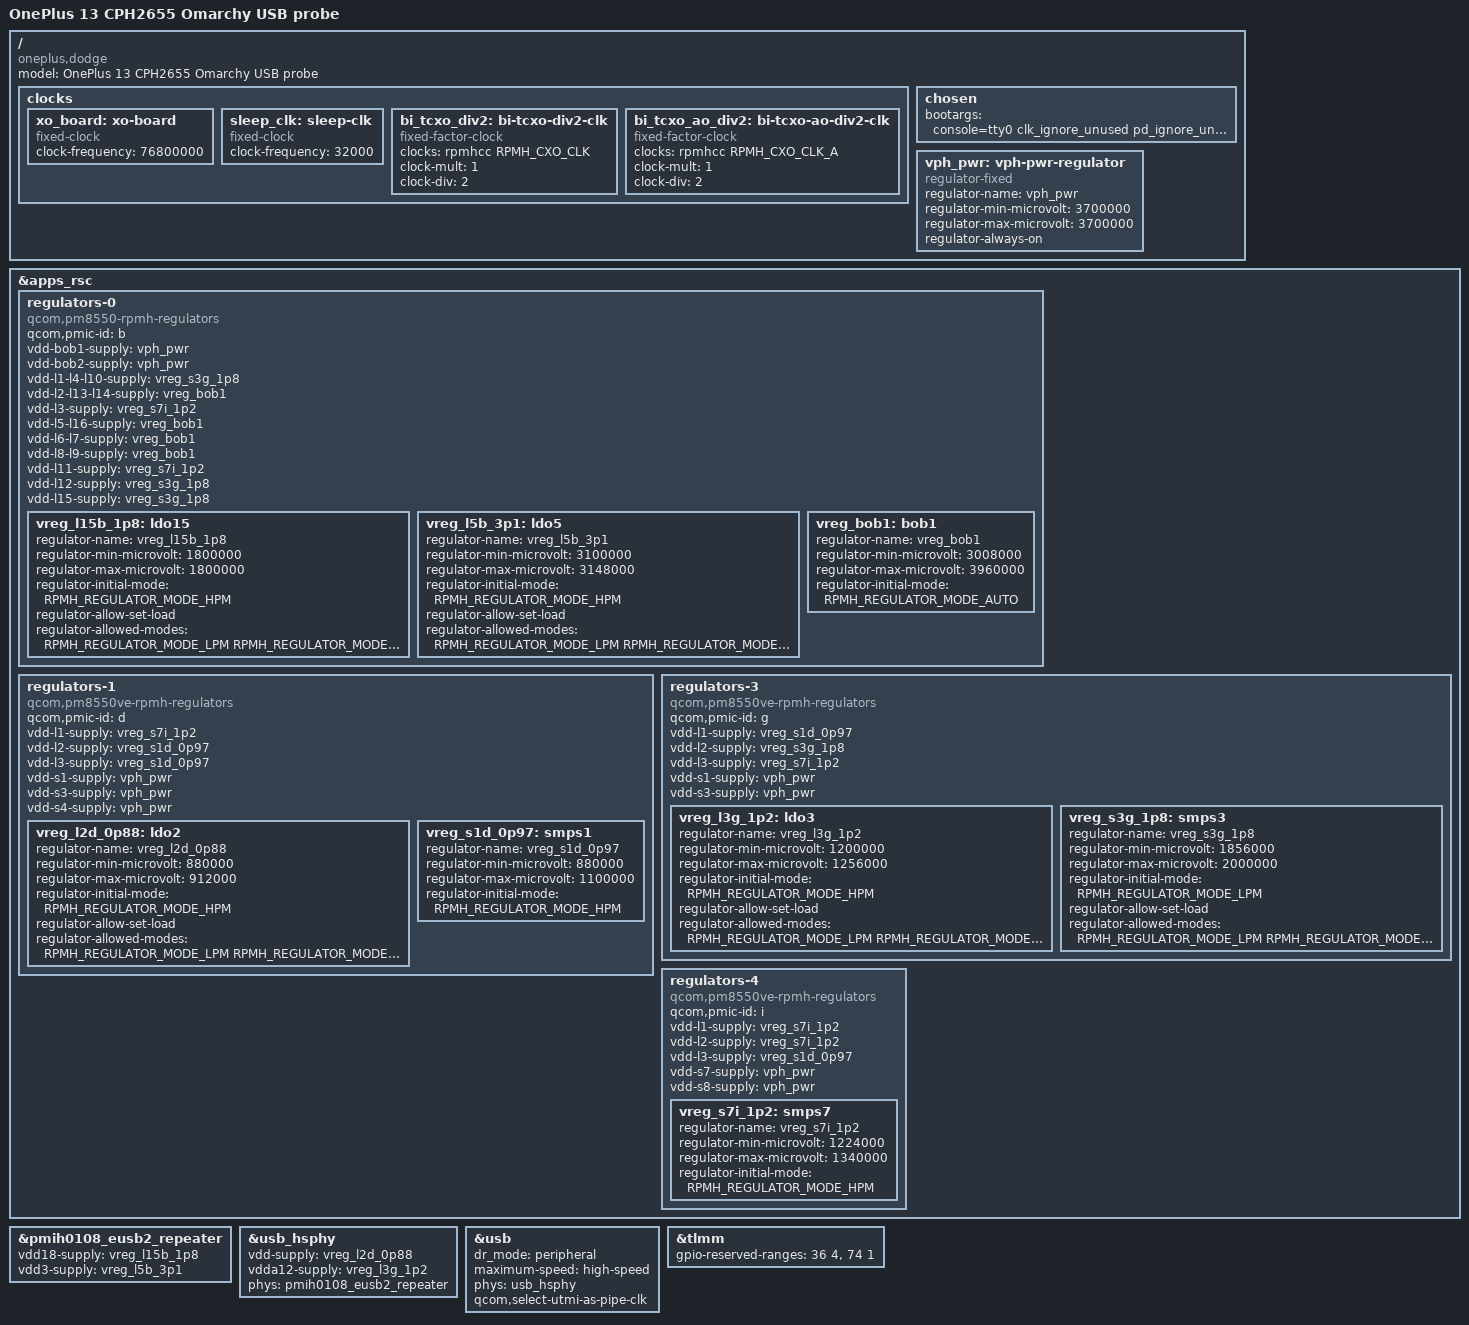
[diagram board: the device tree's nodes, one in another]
// SPDX-License-Identifier: BSD-3-Clause
/* USB-only CPH2655 bring-up. Regulator mapping derived from index986's
 * OnePlus-13-WIP board, commit 1f2047e8663eda76c8b172fd3e040e3b3fa17950.
 * Copyright (c) 2025 index986. All rights reserved.
 * Boot-time memory is supplied separately from this handset's stock capture.
 */
/dts-v1/;
#include <dt-bindings/gpio/gpio.h>
#include <dt-bindings/regulator/qcom,rpmh-regulator.h>
#include "sm8750.dtsi"
#include "pm8550.dtsi"
#define PMK8550VE_SID 8
#include "pm8550ve.dtsi"
#include "pmih0108.dtsi"
#include "pmk8550.dtsi"
#include "sm8750-pmics.dtsi"
/ {

 model = "OnePlus 13 CPH2655 Omarchy USB probe";
 compatible = "oneplus,dodge", "qcom,sm8750";
	clocks {
		xo_board: xo-board {
			compatible = "fixed-clock";
			clock-frequency = <76800000>;
			#clock-cells = <0>;
		};

		sleep_clk: sleep-clk {
			compatible = "fixed-clock";
			clock-frequency = <32000>;
			#clock-cells = <0>;
		};

		bi_tcxo_div2: bi-tcxo-div2-clk {
			compatible = "fixed-factor-clock";
			#clock-cells = <0>;

			clocks = <&rpmhcc RPMH_CXO_CLK>;
			clock-mult = <1>;
			clock-div = <2>;
		};

		bi_tcxo_ao_div2: bi-tcxo-ao-div2-clk {
			compatible = "fixed-factor-clock";
			#clock-cells = <0>;

			clocks = <&rpmhcc RPMH_CXO_CLK_A>;
			clock-mult = <1>;
			clock-div = <2>;
		};
	};

 chosen { bootargs = "console=tty0 clk_ignore_unused pd_ignore_unused regulator_ignore_unused loglevel=8 panic=15 rdinit=/init cpuidle.off=1"; };
 vph_pwr: vph-pwr-regulator { compatible = "regulator-fixed"; regulator-name = "vph_pwr"; regulator-min-microvolt = <3700000>; regulator-max-microvolt = <3700000>; regulator-always-on; };
};
&apps_rsc {
	regulators-0 {
compatible = "qcom,pm8550-rpmh-regulators";
qcom,pmic-id = "b";
vdd-bob1-supply = <&vph_pwr>;
vdd-bob2-supply = <&vph_pwr>;
vdd-l1-l4-l10-supply = <&vreg_s3g_1p8>;
vdd-l2-l13-l14-supply = <&vreg_bob1>;
vdd-l3-supply = <&vreg_s7i_1p2>;
vdd-l5-l16-supply = <&vreg_bob1>;
vdd-l6-l7-supply = <&vreg_bob1>;
vdd-l8-l9-supply = <&vreg_bob1>;
vdd-l11-supply = <&vreg_s7i_1p2>;
vdd-l12-supply = <&vreg_s3g_1p8>;
vdd-l15-supply = <&vreg_s3g_1p8>;
		vreg_l15b_1p8: ldo15 {
			regulator-name = "vreg_l15b_1p8";
			regulator-min-microvolt = <1800000>;
			regulator-max-microvolt = <1800000>;
			regulator-initial-mode = <RPMH_REGULATOR_MODE_HPM>;
			regulator-allow-set-load;
			regulator-allowed-modes = <RPMH_REGULATOR_MODE_LPM
						   RPMH_REGULATOR_MODE_HPM>;
		};
		vreg_l5b_3p1: ldo5 {
			regulator-name = "vreg_l5b_3p1";
			regulator-min-microvolt = <3100000>;
			regulator-max-microvolt = <3148000>;
			regulator-initial-mode = <RPMH_REGULATOR_MODE_HPM>;
			regulator-allow-set-load;
			regulator-allowed-modes = <RPMH_REGULATOR_MODE_LPM
						   RPMH_REGULATOR_MODE_HPM>;
		};
		vreg_bob1: bob1 {
			regulator-name = "vreg_bob1";
			regulator-min-microvolt = <3008000>;
			regulator-max-microvolt = <3960000>;
			regulator-initial-mode = <RPMH_REGULATOR_MODE_AUTO>;
		};
};
	regulators-1 {
compatible = "qcom,pm8550ve-rpmh-regulators";
qcom,pmic-id = "d";
vdd-l1-supply = <&vreg_s7i_1p2>;
vdd-l2-supply = <&vreg_s1d_0p97>;
vdd-l3-supply = <&vreg_s1d_0p97>;
vdd-s1-supply = <&vph_pwr>;
vdd-s3-supply = <&vph_pwr>;
vdd-s4-supply = <&vph_pwr>;
		vreg_l2d_0p88: ldo2 {
			regulator-name = "vreg_l2d_0p88";
			regulator-min-microvolt = <880000>;
			regulator-max-microvolt = <912000>;
			regulator-initial-mode = <RPMH_REGULATOR_MODE_HPM>;
			regulator-allow-set-load;
			regulator-allowed-modes = <RPMH_REGULATOR_MODE_LPM
						   RPMH_REGULATOR_MODE_HPM>;
		};
		vreg_s1d_0p97: smps1 {
			regulator-name = "vreg_s1d_0p97";
			regulator-min-microvolt = <880000>;
			regulator-max-microvolt = <1100000>;
			regulator-initial-mode = <RPMH_REGULATOR_MODE_HPM>;
		};
};
	regulators-3 {
compatible = "qcom,pm8550ve-rpmh-regulators";
qcom,pmic-id = "g";
vdd-l1-supply = <&vreg_s1d_0p97>;
vdd-l2-supply = <&vreg_s3g_1p8>;
vdd-l3-supply = <&vreg_s7i_1p2>;
vdd-s1-supply = <&vph_pwr>;
vdd-s3-supply = <&vph_pwr>;
		vreg_l3g_1p2: ldo3 {
			regulator-name = "vreg_l3g_1p2";
			regulator-min-microvolt = <1200000>;
			regulator-max-microvolt = <1256000>;
			regulator-initial-mode = <RPMH_REGULATOR_MODE_HPM>;
			regulator-allow-set-load;
			regulator-allowed-modes = <RPMH_REGULATOR_MODE_LPM
						   RPMH_REGULATOR_MODE_HPM>;
		};
		vreg_s3g_1p8: smps3 {
			regulator-name = "vreg_s3g_1p8";
			regulator-min-microvolt = <1856000>;
			regulator-max-microvolt = <2000000>;
			regulator-initial-mode = <RPMH_REGULATOR_MODE_LPM>;
			regulator-allow-set-load;
			regulator-allowed-modes = <RPMH_REGULATOR_MODE_LPM
						   RPMH_REGULATOR_MODE_HPM>;
		};
};
	regulators-4 {
compatible = "qcom,pm8550ve-rpmh-regulators";
qcom,pmic-id = "i";
vdd-l1-supply = <&vreg_s7i_1p2>;
vdd-l2-supply = <&vreg_s7i_1p2>;
vdd-l3-supply = <&vreg_s1d_0p97>;
vdd-s7-supply = <&vph_pwr>;
vdd-s8-supply = <&vph_pwr>;
		vreg_s7i_1p2: smps7 {
			regulator-name = "vreg_s7i_1p2";
			regulator-min-microvolt = <1224000>;
			regulator-max-microvolt = <1340000>;
			regulator-initial-mode = <RPMH_REGULATOR_MODE_HPM>;
		};
};
};
&pmih0108_eusb2_repeater { vdd18-supply = <&vreg_l15b_1p8>; vdd3-supply = <&vreg_l5b_3p1>; status = "okay"; };
&usb_hsphy { vdd-supply = <&vreg_l2d_0p88>; vdda12-supply = <&vreg_l3g_1p2>; phys = <&pmih0108_eusb2_repeater>; status = "okay"; };
&usb {
 status = "okay";
 dr_mode = "peripheral";
 maximum-speed = "high-speed";
 phys = <&usb_hsphy>;
 phy-names = "usb2-phy";
 /* No USB3 PHY in this profile: select UTMI explicitly so a normal boot
  * does not depend on the PIPE clock state left behind by fastboot. */
 qcom,select-utmi-as-pipe-clk;
};
&tlmm { gpio-reserved-ranges = <36 4>, <74 1>; };
